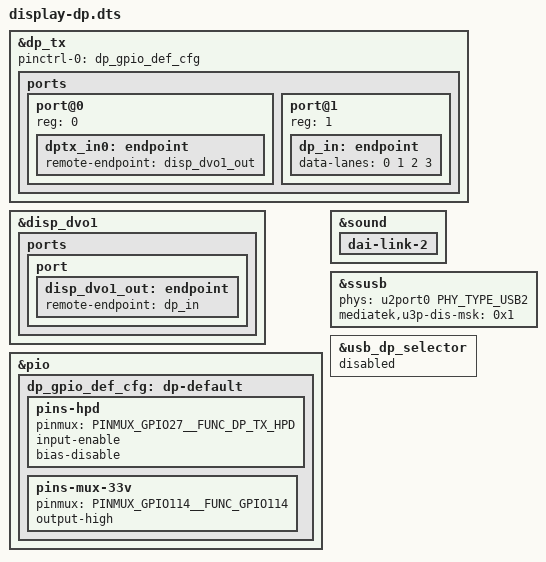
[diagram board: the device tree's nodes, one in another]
/dts-v1/;
/plugin/;

#include <dt-bindings/pinctrl/mt8189-pinfunc.h>
#include <dt-bindings/gpio/gpio.h>
#include <dt-bindings/phy/phy.h>

/ {
	fragment@0 {
		target = <&dp_tx>;
		__overlay__ {
			status = "okay";
			pinctrl-names = "default";
			pinctrl-0 = <&dp_gpio_def_cfg>;
			ports {
				#address-cells = <1>;
				#size-cells = <0>;
				port@0 {
					reg = <0>;
					dptx_in0: endpoint {
						remote-endpoint = <&disp_dvo1_out>;
					};
				};

				port@1 {
					reg = <1>;
					dp_in: endpoint {
						data-lanes = <0 1 2 3>;
					};
				};
			};
		};
	};

	fragment@1 {
		target = <&disp_dvo1>;
		__overlay__ {
			status = "okay";
			ports {
				port {
					disp_dvo1_out: endpoint {
						remote-endpoint = <&dp_in>;
					};
				};
			};
		};
	};

	fragment@2 {
		target = <&pio>;
		__overlay__ {
			dp_gpio_def_cfg: dp-default {
				pins-hpd {
					pinmux = <PINMUX_GPIO27__FUNC_DP_TX_HPD>;
					input-enable;
					bias-disable;
				};
				pins-mux-33v {
					pinmux = <PINMUX_GPIO114__FUNC_GPIO114>;
					output-high;
				};
			};
		};
	};

	fragment@3 {
		target = <&sound>;
		__overlay__ {
			dai-link-2 {
				status = "okay";
			};
		};
	};

	fragment@4 {
		target = <&ssusb>;
		__overlay__ {
			phys = <&u2port0 PHY_TYPE_USB2>;
			mediatek,u3p-dis-msk = <0x1>;
		};
	};

	fragment@5 {
		target = <&usb_dp_selector>;
		__overlay__ {
			status = "disabled";
		};
	};
};
